# USCI_B1__I2C_Mode_1 register map
Vendor: Texas Instruments
Peripheral module from a debugger description file (folder msp430).
Registers are 8-bit, read-write, reset 0x0 unless marked. A register's access mark holds for its fields unless they carry their own. Offsets are as the file gives them; lines under a group give offsets from that group; [hi:lo] are bit positions; {n}, {i} and the like mark numbered series; 'fields as' and 'values as' point back to an identical list; <NAME> marks a mode.

## USCI_B1_I2C_Mode
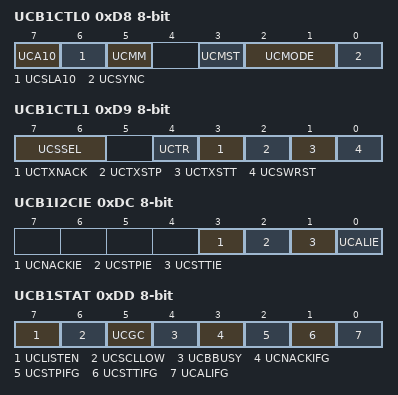
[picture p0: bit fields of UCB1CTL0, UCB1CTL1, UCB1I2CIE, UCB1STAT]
0xD8 UCB1CTL0 — USCI B1 Control Register 0
  [7] UCA10 — 10-bit Address Mode
  [6] UCSLA10 — 10-bit Slave Address Mode
  [5] UCMM — Multi-Master Environment
  [3] UCMST — Sync. Mode: Master Select
  [2:1] UCMODE — Sync. Mode: USCI Mode 1
    {v}=Sync. Mode: USCI Mode: {v} (v=0..3)
  [0] UCSYNC — Sync-Mode 0:UART-Mode / 1:SPI-Mode
0xD9 UCB1CTL1 — USCI B1 Control Register 1
  [7:6] UCSSEL — USCI 1 Clock Source Select 1
    {v}=USCI 0 Clock Source: {v} (v=0..3)
  [4] UCTR — Transmit/Receive Select/Flag
  [3] UCTXNACK — Transmit NACK
  [2] UCTXSTP — Transmit STOP
  [1] UCTXSTT — Transmit START
  [0] UCSWRST — USCI Software Reset
0xDA UCB1BR0 access not given reset not defined — USCI B1 Baud Rate 0
0xDB UCB1BR1 access not given reset not defined — USCI B1 Baud Rate 1
0xDC UCB1I2CIE — USCI B1 I2C Interrupt Enable Register
  [3] UCNACKIE — NACK Condition interrupt enable
  [2] UCSTPIE — STOP Condition interrupt enable
  [1] UCSTTIE — START Condition interrupt enable
  [0] UCALIE — Arbitration Lost interrupt enable
0xDD UCB1STAT — USCI B1 Status Register
  [7] UCLISTEN — USCI Listen mode
  [6] UCSCLLOW — SCL low
  [5] UCGC — General Call address received Flag
  [4] UCBBUSY — Bus Busy Flag
  [3] UCNACKIFG — NAK Condition interrupt Flag
  [2] UCSTPIFG — STOP Condition interrupt Flag
  [1] UCSTTIFG — START Condition interrupt Flag
  [0] UCALIFG — Arbitration Lost interrupt Flag
0xDE UCB1RXBUF access not given reset not defined — USCI B1 Receive Buffer
0xDF UCB1TXBUF access not given reset not defined — USCI B1 Transmit Buffer
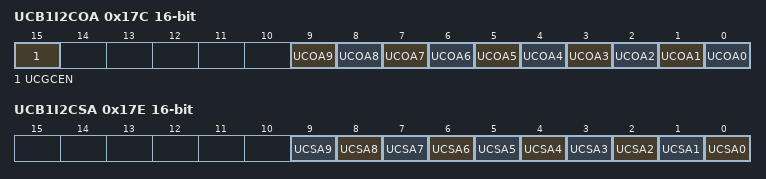
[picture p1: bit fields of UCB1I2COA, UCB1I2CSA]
0x17C UCB1I2COA 16-bit — USCI B1 I2C Own Address
  [15] UCGCEN — I2C General Call enable
  [n] UCOA{n} (n=0..9) — I2C Own Address {n}
0x17E UCB1I2CSA 16-bit — USCI B1 I2C Slave Address
  [n] UCSA{n} (n=0..9) — I2C Slave Address {n}
